AUTOSAR XML (schema 4-2-2)
package /DBC_SysDesc_Can_Network/Pkg_Cluster
  can cluster Can_Network: baudrate=500000, protocol-name=CAN
    can physical channel Can_Network_Channel: comm-connectors=Conn_Can_Network_CANNODE_0_BMS
      frame TMR_3: id 0x328, to BMS, frame-length=8, can-addressing-mode=STANDARD, can-frame-rx-behavior=ANY
        carries pdu TMR_3: packing-byte-order=big-endian, start-position=7, update-indication-bit-position=-1
        pdu TMR_3: length=8, transmission-mode-false-timing=cyclic-timing={time-offset=0.0, time-period=0.05}, transmission-mode-true-timing=cyclic-timing={time-offset=0.0, time-period=0.05}
          transmission-mode-conditions:
            {data-filter={data-filter-type=NEW-IS-WITHIN, max=1021, min=0, offset=0}, i-signal-in-i-pdu=TMR_VoltageHV}
            {data-filter={data-filter-type=NEW-IS-WITHIN, max=2044, min=0}, i-signal-in-i-pdu=TMR_CurrentHV}
          signal TMR_VoltageHV: start 12, 10 bit, big-endian, init-value=0, base-type=uint16, compu {raw=phys for phys 0..1021; unit V}, update-indication-bit-position=-1, to BMS  # HV voltage at the DC/AC converter"
          signal TMR_CurrentHV: start 7, 11 bit, big-endian, init-value=1023, base-type=uint16, compu {raw=phys+1023 for phys -1023..1021; unit Ampere}, update-indication-bit-position=-1, to BMS  # HV current at the DC/AC converter"
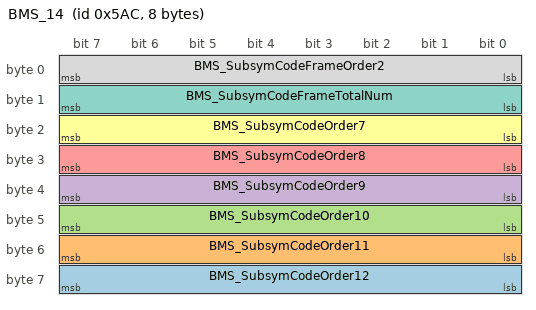
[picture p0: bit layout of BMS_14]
      frame BMS_14: id 0x5AC, from BMS, frame-length=8, can-addressing-mode=STANDARD
        carries pdu BMS_14: packing-byte-order=big-endian, start-position=7, update-indication-bit-position=-1
        pdu BMS_14: length=8, transmission-mode-false-timing=cyclic-timing={time-offset=0.0, time-period=1.0}, transmission-mode-true-timing=cyclic-timing={time-offset=0.0, time-period=1.0}
          transmission-mode-conditions:
            {data-filter={data-filter-type=ALWAYS, max=255, min=0, offset=0}, i-signal-in-i-pdu=BMS_SubsymCodeOrder12}
            {data-filter={data-filter-type=ALWAYS, max=255, min=0, offset=0}, i-signal-in-i-pdu=BMS_SubsymCodeOrder11}
            {data-filter={data-filter-type=ALWAYS, max=255, min=0, offset=0}, i-signal-in-i-pdu=BMS_SubsymCodeOrder10}
            {data-filter={data-filter-type=ALWAYS, max=255, min=0, offset=0}, i-signal-in-i-pdu=BMS_SubsymCodeOrder9}
            {data-filter={data-filter-type=ALWAYS, max=255, min=0, offset=0}, i-signal-in-i-pdu=BMS_SubsymCodeOrder8}
            {data-filter={data-filter-type=ALWAYS, max=255, min=0, offset=0}, i-signal-in-i-pdu=BMS_SubsymCodeOrder7}
            {data-filter={data-filter-type=ALWAYS, max=255, min=0, offset=0}, i-signal-in-i-pdu=BMS_SubsymCodeFrameTotalNum}
            {data-filter={data-filter-type=ALWAYS, max=255, min=0, offset=0}, i-signal-in-i-pdu=BMS_SubsymCodeFrameOrder2}
          signal BMS_SubsymCodeOrder12: start 63, 8 bit, big-endian, init-value=0, base-type=uint8, compu {raw=phys for phys 0..255}, update-indication-bit-position=-1  # ??????????????????????????"
          signal BMS_SubsymCodeOrder11: start 55, 8 bit, big-endian, init-value=0, base-type=uint8, compu {raw=phys for phys 0..255}, update-indication-bit-position=-1  # ?????????????????????????"
          signal BMS_SubsymCodeOrder10: start 47, 8 bit, big-endian, init-value=0, base-type=uint8, compu {raw=phys for phys 0..255}, update-indication-bit-position=-1  # ????????????????????????"
          signal BMS_SubsymCodeOrder9: start 39, 8 bit, big-endian, init-value=0, base-type=uint8, compu {raw=phys for phys 0..255}, update-indication-bit-position=-1  # ???????????????????????"
          signal BMS_SubsymCodeOrder8: start 31, 8 bit, big-endian, init-value=0, base-type=uint8, compu {raw=phys for phys 0..255}, update-indication-bit-position=-1  # ???????????????????????"
          signal BMS_SubsymCodeOrder7: start 23, 8 bit, big-endian, init-value=0, base-type=uint8, compu {raw=phys for phys 0..255}, update-indication-bit-position=-1  # ????????????????????????"
          signal BMS_SubsymCodeFrameTotalNum: start 15, 8 bit, big-endian, init-value=0, base-type=uint8, compu {raw=phys for phys 0..255}, update-indication-bit-position=-1  # ????????????????"
          signal BMS_SubsymCodeFrameOrder2: start 7, 8 bit, big-endian, init-value=0, base-type=uint8, compu {raw=phys for phys 0..255}, update-indication-bit-position=-1  # ???????????????2"
package /DBC_SysDesc_Can_Network/Pkg_Ecu
  ecu instance BMS: com-configuration-gw-time-base=0.005, com-configuration-rx-time-base=0.01, com-configuration-tx-time-base=0.01, sleep-mode-supported=false, wake-up-over-bus-supported=false
    can communication controller Can_Network_CANNODE_0: can-controller-attributes=can-controller-configuration={prop-seg=2, sync-jump-width=1, time-seg-1=12, time-seg-2=5}
    can communication connector Conn_Can_Network_CANNODE_0_BMS: comm-controller=Can_Network_CANNODE_0
package /DBC_SysDesc_Can_Network/Pkg_Units
  unit Ampere
  unit V
